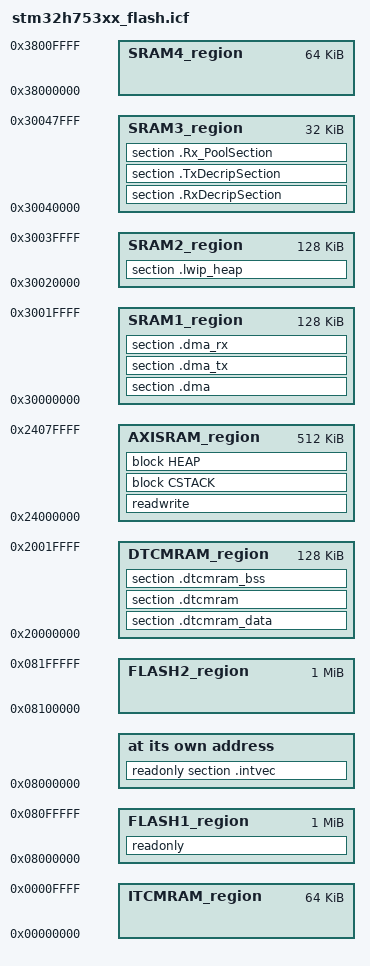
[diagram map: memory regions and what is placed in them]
/*###ICF### Section handled by ICF editor, don't touch! ****/
/*-Editor annotation file-*/
/* IcfEditorFile="$TOOLKIT_DIR$\config\ide\IcfEditor\cortex_v1_0.xml" */
/*-Specials-*/
define symbol __ICFEDIT_intvec_start__ = 0x08000000;
/*-Memory Regions-*/
define symbol __ICFEDIT_region_FLASH1_start__ = 0x08000000;
define symbol __ICFEDIT_region_FLASH1_end__   = 0x080FFFFF;
define symbol __ICFEDIT_region_FLASH2_start__ = 0x08100000;
define symbol __ICFEDIT_region_FLASH2_end__   = 0x081FFFFF;

define symbol __ICFEDIT_region_ITCMRAM_start__ = 0x00000000;
define symbol __ICFEDIT_region_ITCMRAM_end__   = 0x0000FFFF;
define symbol __ICFEDIT_region_DTCMRAM_start__ = 0x20000000;
define symbol __ICFEDIT_region_DTCMRAM_end__   = 0x2001FFFF;
define symbol __ICFEDIT_region_AXISRAM_start__ = 0x24000000;
define symbol __ICFEDIT_region_AXISRAM_end__   = 0x2407FFFF;
define symbol __ICFEDIT_region_SRAM1_start__   = 0x30000000;
define symbol __ICFEDIT_region_SRAM1_end__     = 0x3001FFFF;
define symbol __ICFEDIT_region_SRAM2_start__   = 0x30020000;
define symbol __ICFEDIT_region_SRAM2_end__     = 0x3003FFFF;
define symbol __ICFEDIT_region_SRAM3_start__   = 0x30040000;
define symbol __ICFEDIT_region_SRAM3_end__     = 0x30047FFF;
define symbol __ICFEDIT_region_SRAM4_start__   = 0x38000000;
define symbol __ICFEDIT_region_SRAM4_end__     = 0x3800FFFF;
/*-Sizes-*/
define symbol __ICFEDIT_size_cstack__ = 0x400;
define symbol __ICFEDIT_size_heap__   = 0x200;
/**** End of ICF editor section. ###ICF###*/


define memory mem with size = 4G;
define region FLASH1_region   = mem:[from __ICFEDIT_region_FLASH1_start__ to __ICFEDIT_region_FLASH1_end__];
define region FLASH2_region   = mem:[from __ICFEDIT_region_FLASH2_start__ to __ICFEDIT_region_FLASH2_end__];
define region ITCMRAM_region  = mem:[from __ICFEDIT_region_ITCMRAM_start__ to __ICFEDIT_region_ITCMRAM_end__];
define region DTCMRAM_region  = mem:[from __ICFEDIT_region_DTCMRAM_start__ to __ICFEDIT_region_DTCMRAM_end__];
define region AXISRAM_region  = mem:[from __ICFEDIT_region_AXISRAM_start__ to __ICFEDIT_region_AXISRAM_end__];
define region SRAM1_region    = mem:[from __ICFEDIT_region_SRAM1_start__ to __ICFEDIT_region_SRAM1_end__];
define region SRAM2_region    = mem:[from __ICFEDIT_region_SRAM2_start__ to __ICFEDIT_region_SRAM2_end__];
define region SRAM3_region    = mem:[from __ICFEDIT_region_SRAM3_start__ to __ICFEDIT_region_SRAM3_end__];
define region SRAM4_region    = mem:[from __ICFEDIT_region_SRAM4_start__ to __ICFEDIT_region_SRAM4_end__];

define block CSTACK    with alignment = 8, size = __ICFEDIT_size_cstack__   { };
define block HEAP      with alignment = 8, size = __ICFEDIT_size_heap__     { };

initialize by copy { readwrite, section .dtcmram_data };
initialize by zeroing { section .dtcmram, section .dtcmram_bss };
do not initialize  { section .noinit };

place at address mem:__ICFEDIT_intvec_start__ { readonly section .intvec };

place in FLASH1_region   { readonly };
place in AXISRAM_region  { readwrite, block CSTACK, block HEAP };

/* STM32ZERO sections */
/* DTCMRAM: .dtcmram_data (initialized), .dtcmram/.dtcmram_bss (zero-init) */
place in DTCMRAM_region  { section .dtcmram_data, section .dtcmram, section .dtcmram_bss };
place in SRAM1_region    { section .dma, section .dma_tx, section .dma_rx };
place in SRAM2_region    { section .lwip_heap };
place in SRAM3_region    { section .RxDecripSection, section .TxDecripSection, section .Rx_PoolSection };
